# STM32N655xx register map
File version: 1.0
Registers are 32-bit, read-write, reset 0x0 unless marked. A register's access mark holds for its fields unless they carry their own. Offsets are from the block's base; [hi:lo] are bit positions; {n}, {i} and the like mark numbered series.

## EXTI — External Interrupt/Event Controller
Base 0x46025000
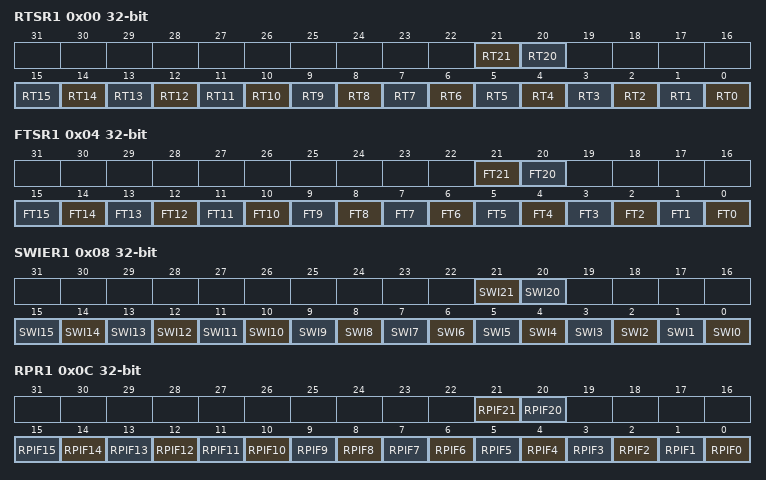
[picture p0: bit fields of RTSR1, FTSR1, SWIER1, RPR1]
0x00 RTSR1 — EXTI Rising Trigger Selection Register 1
  [21] RT21 — Rising trigger configuration for input line 21
  [20] RT20 — Rising trigger configuration for input line 20
  [n] RT{n} (n=0..15) — Rising trigger configuration for input line {n}
0x04 FTSR1 — EXTI Falling Trigger Selection Register 1
  [21] FT21 — Falling trigger configuration for input line 21
  [20] FT20 — Falling trigger configuration for input line 20
  [n] FT{n} (n=0..15) — Falling trigger configuration for input line {n}
0x08 SWIER1 — EXTI Software Interrupt event Register 1
  [21] SWI21 — Software Interrupt on line 21
  [20] SWI20 — Software Interrupt on line 20
  [n] SWI{n} (n=0..15) — Software Interrupt on line {n}
0x0C RPR1 — EXTI Rising Pending Register 1
  [21] RPIF21 — Rising Pending Interrupt Flag on line 21
  [20] RPIF20 — Rising Pending Interrupt Flag on line 20
  [n] RPIF{n} (n=0..15) — Rising Pending Interrupt Flag on line {n}
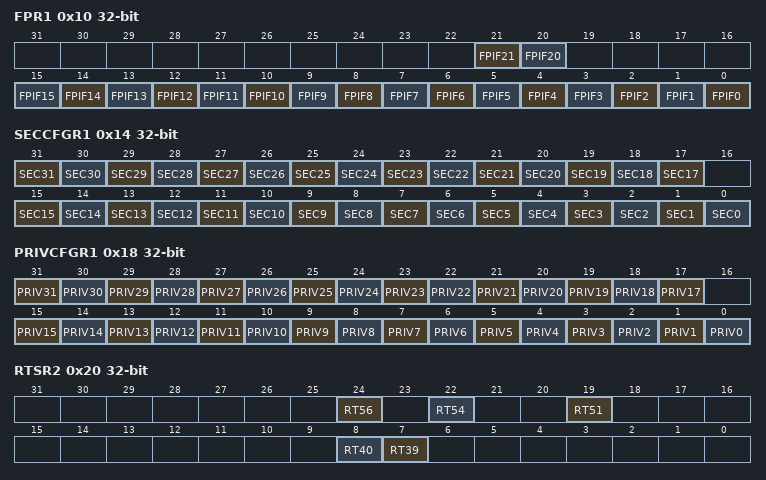
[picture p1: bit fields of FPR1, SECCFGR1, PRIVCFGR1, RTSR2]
0x10 FPR1 — EXTI Falling Pending Register 1
  [21] FPIF21 — Falling Pending Interrupt Flag on line 21
  [20] FPIF20 — Falling Pending Interrupt Flag on line 20
  [n] FPIF{n} (n=0..15) — Falling Pending Interrupt Flag on line {n}
0x14 SECCFGR1 — EXTI Security Configuration Register 1
  [n] SEC{n} (n=17..31) — Security enable on line {n}
  [n] SEC{n} (n=0..15) — Security enable on line {n}
0x18 PRIVCFGR1 — EXTI Privilege Configuration Register 1
  [n] PRIV{n} (n=17..31) — Privilege enable on line {n}
  [n] PRIV{n} (n=0..15) — Privilege enable on line {n}
0x20 RTSR2 — EXTI Rising Trigger Selection Register 2
  [24] RT56 — Rising trigger configuration for input line 56
  [22] RT54 — Rising trigger configuration for input line 54
  [19] RT51 — Rising trigger configuration for input line 51
  [8] RT40 — Rising trigger configuration for input line 40
  [7] RT39 — Rising trigger configuration for input line 39
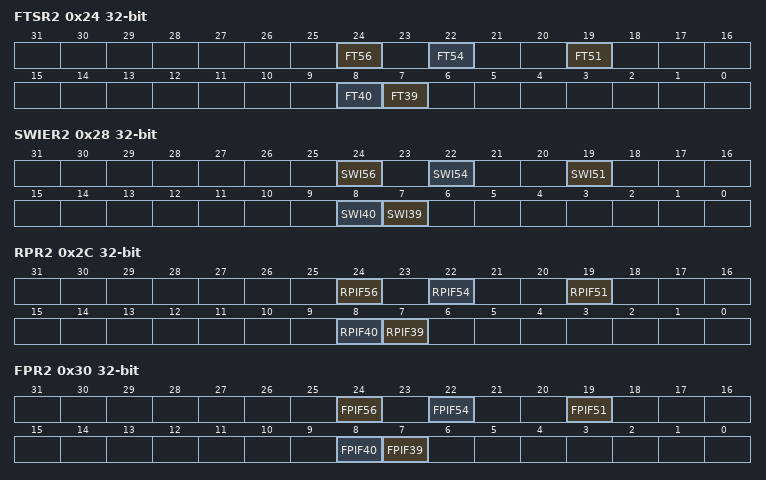
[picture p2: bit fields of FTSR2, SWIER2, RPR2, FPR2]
0x24 FTSR2 — EXTI Falling Trigger Selection Register 2
  [24] FT56 — Falling trigger configuration for input line 56
  [22] FT54 — Falling trigger configuration for input line 54
  [19] FT51 — Falling trigger configuration for input line 51
  [8] FT40 — Falling trigger configuration for input line 40
  [7] FT39 — Falling trigger configuration for input line 39
0x28 SWIER2 — EXTI Software Interrupt event Register 2
  [24] SWI56 — Software Interrupt on line 56
  [22] SWI54 — Software Interrupt on line 54
  [19] SWI51 — Software Interrupt on line 51
  [8] SWI40 — Software Interrupt on line 40
  [7] SWI39 — Software Interrupt on line 39
0x2C RPR2 — EXTI Rising Pending Register 2
  [24] RPIF56 — Rising Pending Interrupt Flag on line 56
  [22] RPIF54 — Rising Pending Interrupt Flag on line 54
  [19] RPIF51 — Rising Pending Interrupt Flag on line 51
  [8] RPIF40 — Rising Pending Interrupt Flag on line 40
  [7] RPIF39 — Rising Pending Interrupt Flag on line 39
0x30 FPR2 — EXTI Falling Pending Register 2
  [24] FPIF56 — Falling Pending Interrupt Flag on line 56
  [22] FPIF54 — Falling Pending Interrupt Flag on line 54
  [19] FPIF51 — Falling Pending Interrupt Flag on line 51
  [8] FPIF40 — Falling Pending Interrupt Flag on line 40
  [7] FPIF39 — Falling Pending Interrupt Flag on line 39
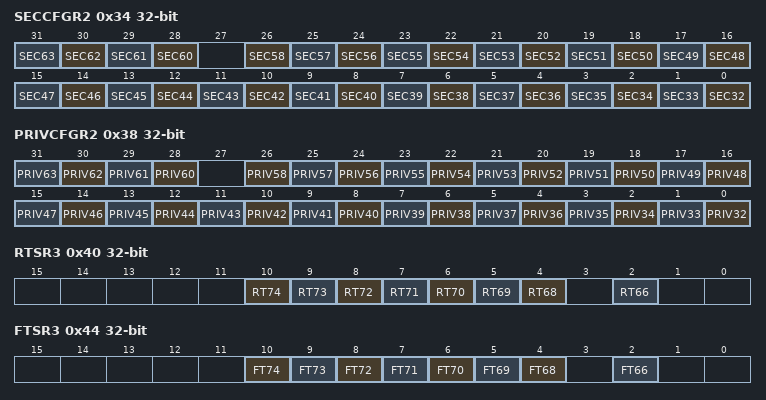
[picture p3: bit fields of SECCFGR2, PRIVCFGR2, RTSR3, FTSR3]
0x34 SECCFGR2 — EXTI Security Configuration Register 2
  [n-32] SEC{n} (n=60..63) — Security enable on line {n}
  [n-32] SEC{n} (n=32..58) — Security enable on line {n}
0x38 PRIVCFGR2 — EXTI Privilege Configuration Register 2
  [n-32] PRIV{n} (n=60..63) — Privilege enable on line {n}
  [n-32] PRIV{n} (n=32..58) — Privilege enable on line {n}
0x40 RTSR3 — EXTI Rising Trigger Selection Register 3
  [n-64] RT{n} (n=68..74) — Rising trigger configuration for input line {n}
  [2] RT66 — Rising trigger configuration for input line 66
0x44 FTSR3 — EXTI Falling Trigger Selection Register 3
  [n-64] FT{n} (n=68..74) — Falling trigger configuration for input line {n}
  [2] FT66 — Falling trigger configuration for input line 66
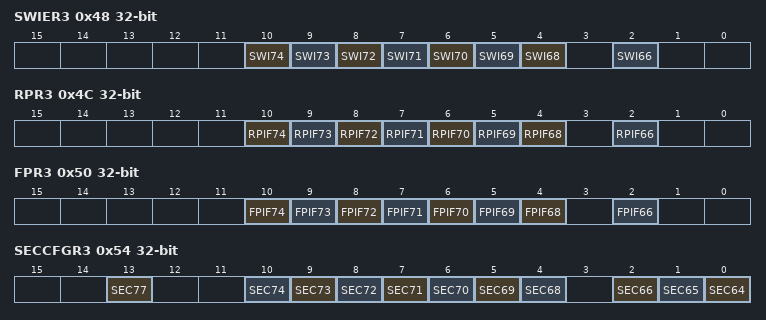
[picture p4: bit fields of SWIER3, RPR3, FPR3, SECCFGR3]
0x48 SWIER3 — EXTI Software Interrupt event Register 3
  [n-64] SWI{n} (n=68..74) — Software Interrupt on line {n}
  [2] SWI66 — Software Interrupt on line 66
0x4C RPR3 — EXTI Rising Pending Register 3
  [n-64] RPIF{n} (n=68..74) — Rising Pending Interrupt Flag on line {n}
  [2] RPIF66 — Rising Pending Interrupt Flag on line 66
0x50 FPR3 — EXTI Falling Pending Register 3
  [n-64] FPIF{n} (n=70..74) — Falling Pending Interrupt Flag on line {n}
  [5] FPIF69 — Falling Pending Interrupt Flag online 69
  [4] FPIF68 — Falling Pending Interrupt Flag on line 68
  [2] FPIF66 — Falling Pending Interrupt Flag on line 66
0x54 SECCFGR3 — EXTI Security Configuration Register 3
  [13] SEC77 — Security enable on line 77
  [n-64] SEC{n} (n=68..74) — Security enable on line {n}
  [2] SEC66 — Security enable on line 66
  [1] SEC65 — Security enable on line 65
  [0] SEC64 — Security enable on line 64
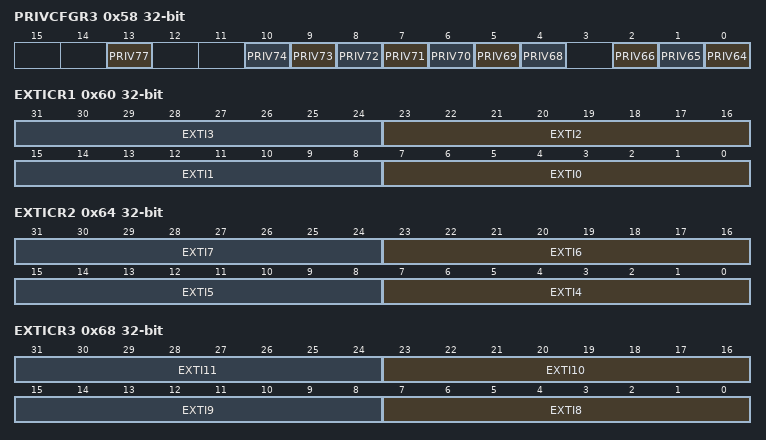
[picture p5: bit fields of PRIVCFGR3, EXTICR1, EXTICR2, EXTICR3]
0x58 PRIVCFGR3 — EXTI Privilege Configuration Register 3
  [13] PRIV77 — Privilege enable on line 77
  [n-64] PRIV{n} (n=68..74) — Privilege enable on line {n}
  [2] PRIV66 — Privilege enable on line 66
  [1] PRIV65 — Privilege enable on line 65
  [0] PRIV64 — Privilege enable on line 64
0x60 EXTICR1 — EXIT External Interrupt Configuration Register, 0x60 -- 0x6C
  [8n+7:8n] EXTI{n} (n=0..3) — EXTI {n} configuration
0x64 EXTICR2 — EXIT External Interrupt Configuration Register, 0x60 -- 0x6C
  [8n-25:8n-32] EXTI{n} (n=4..7) — EXTI {n} configuration
0x68 EXTICR3 — EXIT External Interrupt Configuration Register, 0x60 -- 0x6C
  [8n-57:8n-64] EXTI{n} (n=8..11) — EXTI {n} configuration
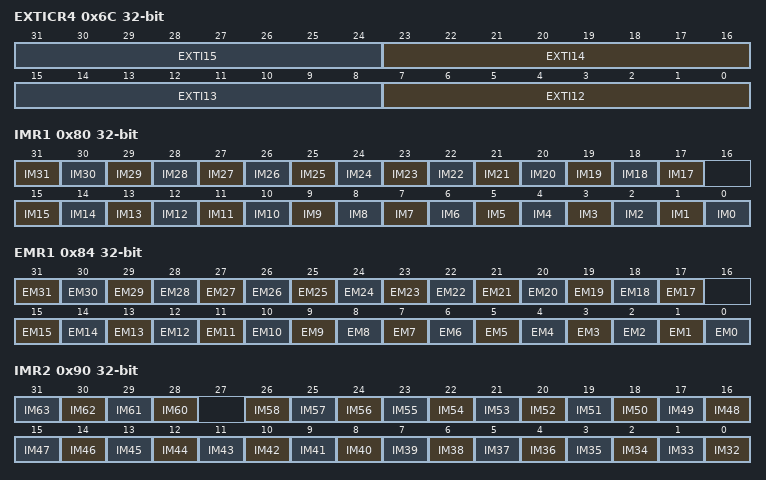
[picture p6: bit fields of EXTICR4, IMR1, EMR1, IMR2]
0x6C EXTICR4 — EXIT External Interrupt Configuration Register, 0x60 -- 0x6C
  [8n-89:8n-96] EXTI{n} (n=12..15) — EXTI {n} configuration
0x70 LOCKR — EXTI Lock Register
  [0] LOCK — Security and privilege configuration lock
0x80 IMR1 — EXTI Interrupt Mask Register 1
  [n] IM{n} (n=17..31) — Interrupt Mask on line {n}
  [n] IM{n} (n=0..15) — Interrupt Mask on line {n}
0x84 EMR1 — EXTI Event Mask Register 1
  [n] EM{n} (n=17..31) — Event Mask on line {n}
  [n] EM{n} (n=0..15) — Event Mask on line {n}
0x90 IMR2 — EXTI Interrupt Mask Register 2
  [n-32] IM{n} (n=60..63) — Interrupt Mask on line {n}
  [n-32] IM{n} (n=32..58) — Interrupt Mask on line {n}
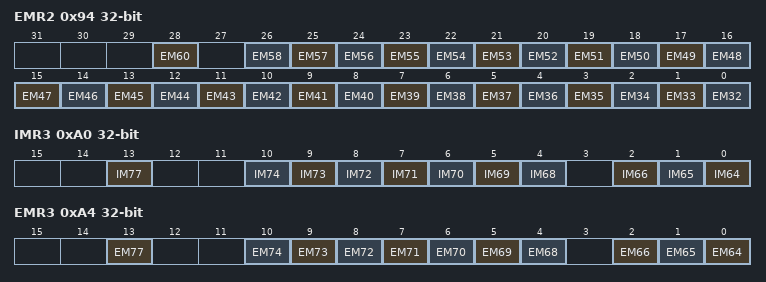
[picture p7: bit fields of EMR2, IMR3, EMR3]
0x94 EMR2 — EXTI Event Mask Register 2
  [28] EM60 — Event Mask on line 60
  [n-32] EM{n} (n=32..58) — Event Mask on line {n}
0xA0 IMR3 — EXTI Interrupt Mask Register 3
  [13] IM77 — Interrupt Mask on line 77
  [n-64] IM{n} (n=68..74) — Interrupt Mask on line {n}
  [2] IM66 — Interrupt Mask on line 66
  [1] IM65 — Interrupt Mask on line 65
  [0] IM64 — Interrupt Mask on line 64
0xA4 EMR3 — EXTI Event Mask Register 3
  [13] EM77 — Event Mask on line 77
  [n-64] EM{n} (n=68..74) — Event Mask on line {n}
  [2] EM66 — Event Mask on line 66
  [1] EM65 — Event Mask on line 65
  [0] EM64 — Event Mask on line 64
